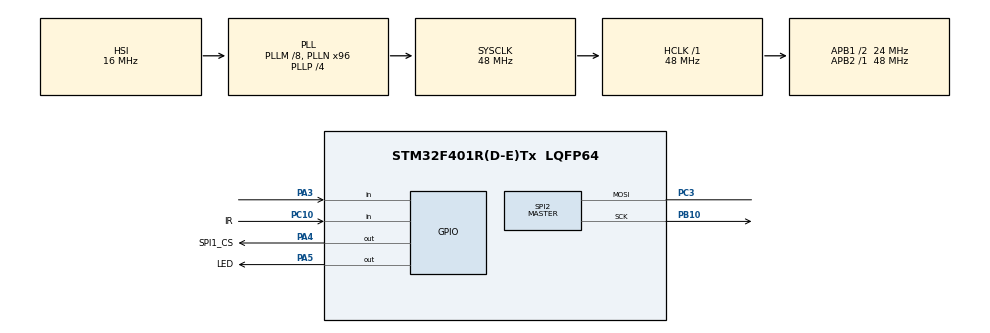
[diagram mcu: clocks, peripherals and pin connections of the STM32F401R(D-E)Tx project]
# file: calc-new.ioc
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Mcu.Family=STM32F4
PC3.Mode=Simplex_Bidirectional_Master
RCC.CortexFreq_Value=48000000
FREERTOS.Tasks01=calcTask,0,128,StartDefaultTask,Default,NULL,Dynamic,NULL,NULL
PC10.GPIO_Label=IR
SPI2.VirtualType=VM_MASTER
PB10.Mode=Simplex_Bidirectional_Master
PC10.Signal=GPIO_Input
PH1\ -\ OSC_OUT.Mode=HSE-External-Oscillator
RCC.APB1CLKDivider=RCC_HCLK_DIV2
PA5.PinState=GPIO_PIN_SET
RCC.SYSCLKSource=RCC_SYSCLKSOURCE_PLLCLK
ProjectManager.StackSize=0x400
PA13.Signal=SYS_JTMS-SWDIO
PH0\ -\ OSC_IN.Mode=HSE-External-Oscillator
PH0\ -\ OSC_IN.Signal=RCC_OSC_IN
ProjectManager.TargetToolchain=STM32CubeIDE
RCC.HCLKFreq_Value=48000000
RCC.APB2TimFreq_Value=48000000
PC3.Signal=SPI2_MOSI
TIM4.Prescaler=48-1
RCC.LSE_VALUE=32768
RCC.AHBFreq_Value=48000000
PB10.Signal=SPI2_SCK
PA5.Signal=GPIO_Output
RCC.HSE_VALUE=25000000
PH1\ -\ OSC_OUT.Signal=RCC_OSC_OUT
board=custom
RCC.VCOOutputFreq_Value=192000000
RCC.APB2Freq_Value=48000000
PA14.Mode=Serial_Wire
TIM4.Period=6553
VP_FREERTOS_VS_CMSIS_V1.Mode=CMSIS_V1
PA13.Mode=Serial_Wire
Mcu.Name=STM32F401R(D-E)Tx
RCC.48MHZClocksFreq_Value=48000000
PA4.Signal=GPIO_Output
RCC.SYSCLKFreq_VALUE=48000000
Mcu.Package=LQFP64
SPI2.Mode=SPI_MODE_MASTER
PA5.GPIO_Label=LED
PA14.Signal=SYS_JTCK-SWCLK
ProjectManager.HeapSize=0x200
RCC.HSI_VALUE=16000000
VP_TIM4_VS_ClockSourceINT.Mode=Internal
RCC.PLLP=RCC_PLLP_DIV4
NVIC.PriorityGroup=NVIC_PRIORITYGROUP_4
RCC.PLLM=8
RCC.PLLN=96
RCC.APB1TimFreq_Value=48000000
SPI2.Direction=SPI_DIRECTION_1LINE
RCC.APB1Freq_Value=24000000
PA4.GPIO_Label=SPI1_CS
PA3.Signal=GPIO_Input

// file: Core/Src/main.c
/* USER CODE BEGIN Header */
/**
  ******************************************************************************
  * @file           : main.c
  * @brief          : Main program body
  ******************************************************************************
  * @attention
  *
  * <h2><center>&copy; Copyright (c) 2021 STMicroelectronics.
  * All rights reserved.</center></h2>
  *
  * This software component is licensed by ST under BSD 3-Clause license,
  * the "License"; You may not use this file except in compliance with the
  * License. You may obtain a copy of the License at:
  *                        opensource.org/licenses/BSD-3-Clause
  *
  ******************************************************************************
  */
/* USER CODE END Header */
#include "main.h"
#include "cmsis_os.h"

/* USER CODE BEGIN Includes */
#include "ir_remote.h"
#include "tic8213.h"
#include "nec.h"
#include "calc.h"
#include "stm32f4xx_hal_tim.h"

/* USER CODE END Includes */

SPI_HandleTypeDef hspi2;

TIM_HandleTypeDef htim4;

osThreadId calcTaskHandle;

void SystemClock_Config(void);
static void MX_GPIO_Init(void);
static void MX_SPI2_Init(void);
static void MX_TIM4_Init(void);
void StartDefaultTask(void const * argument);

int main(void)
{

  /* MCU Configuration--------------------------------------------------------*/

  /* Reset of all peripherals, Initializes the Flash interface and the Systick. */
  HAL_Init();

  /* Configure the system clock */
  SystemClock_Config();

  /* Initialize all configured peripherals */
  MX_GPIO_Init();
  MX_SPI2_Init();
  MX_TIM4_Init();

  /* Create the thread(s) */
  /* definition and creation of calcTask */
  osThreadDef(calcTask, StartDefaultTask, osPriorityNormal, 0, 128);
  calcTaskHandle = osThreadCreate(osThread(calcTask), NULL);

  /* Start scheduler */
  osKernelStart();

  /* We should never get here as control is now taken by the scheduler */
  /* Infinite loop */
  while (1)
  {

  }
}

void SystemClock_Config(void)
{
  RCC_OscInitTypeDef RCC_OscInitStruct = {0};
  RCC_ClkInitTypeDef RCC_ClkInitStruct = {0};

  /** Configure the main internal regulator output voltage
  */
  __HAL_RCC_PWR_CLK_ENABLE();
  __HAL_PWR_VOLTAGESCALING_CONFIG(PWR_REGULATOR_VOLTAGE_SCALE2);
  /** Initializes the RCC Oscillators according to the specified parameters
  * in the RCC_OscInitTypeDef structure.
  */
  RCC_OscInitStruct.OscillatorType = RCC_OSCILLATORTYPE_HSI;
  RCC_OscInitStruct.HSIState = RCC_HSI_ON;
  RCC_OscInitStruct.HSICalibrationValue = RCC_HSICALIBRATION_DEFAULT;
  RCC_OscInitStruct.PLL.PLLState = RCC_PLL_ON;
  RCC_OscInitStruct.PLL.PLLSource = RCC_PLLSOURCE_HSI;
  RCC_OscInitStruct.PLL.PLLM = 8;
  RCC_OscInitStruct.PLL.PLLN = 96;
  RCC_OscInitStruct.PLL.PLLP = RCC_PLLP_DIV4;
  RCC_OscInitStruct.PLL.PLLQ = 4;
  if (HAL_RCC_OscConfig(&RCC_OscInitStruct) != HAL_OK)
  {
    Error_Handler();
  }
  /** Initializes the CPU, AHB and APB buses clocks
  */
  RCC_ClkInitStruct.ClockType = RCC_CLOCKTYPE_HCLK|RCC_CLOCKTYPE_SYSCLK
                              |RCC_CLOCKTYPE_PCLK1|RCC_CLOCKTYPE_PCLK2;
  RCC_ClkInitStruct.SYSCLKSource = RCC_SYSCLKSOURCE_PLLCLK;
  RCC_ClkInitStruct.AHBCLKDivider = RCC_SYSCLK_DIV1;
  RCC_ClkInitStruct.APB1CLKDivider = RCC_HCLK_DIV2;
  RCC_ClkInitStruct.APB2CLKDivider = RCC_HCLK_DIV1;

  if (HAL_RCC_ClockConfig(&RCC_ClkInitStruct, FLASH_LATENCY_1) != HAL_OK)
  {
    Error_Handler();
  }
}

static void MX_SPI2_Init(void)
{

  /* SPI2 parameter configuration*/
  hspi2.Instance = SPI2;
  hspi2.Init.Mode = SPI_MODE_MASTER;
  hspi2.Init.Direction = SPI_DIRECTION_1LINE;
  hspi2.Init.DataSize = SPI_DATASIZE_8BIT;
  hspi2.Init.CLKPolarity = SPI_POLARITY_LOW;
  hspi2.Init.CLKPhase = SPI_PHASE_1EDGE;
  hspi2.Init.NSS = SPI_NSS_SOFT;
  hspi2.Init.BaudRatePrescaler = SPI_BAUDRATEPRESCALER_2;
  hspi2.Init.FirstBit = SPI_FIRSTBIT_MSB;
  hspi2.Init.TIMode = SPI_TIMODE_DISABLE;
  hspi2.Init.CRCCalculation = SPI_CRCCALCULATION_DISABLE;
  hspi2.Init.CRCPolynomial = 10;
  if (HAL_SPI_Init(&hspi2) != HAL_OK)
  {
    Error_Handler();
  }

}

static void MX_TIM4_Init(void)
{

  TIM_ClockConfigTypeDef sClockSourceConfig = {0};
  TIM_MasterConfigTypeDef sMasterConfig = {0};

  htim4.Instance = TIM4;
  htim4.Init.Prescaler = 48-1;
  htim4.Init.CounterMode = TIM_COUNTERMODE_UP;
  htim4.Init.Period = 6553;
  htim4.Init.ClockDivision = TIM_CLOCKDIVISION_DIV1;
  htim4.Init.AutoReloadPreload = TIM_AUTORELOAD_PRELOAD_DISABLE;
  if (HAL_TIM_Base_Init(&htim4) != HAL_OK)
  {
    Error_Handler();
  }
  sClockSourceConfig.ClockSource = TIM_CLOCKSOURCE_INTERNAL;
  if (HAL_TIM_ConfigClockSource(&htim4, &sClockSourceConfig) != HAL_OK)
  {
    Error_Handler();
  }
  sMasterConfig.MasterOutputTrigger = TIM_TRGO_RESET;
  sMasterConfig.MasterSlaveMode = TIM_MASTERSLAVEMODE_DISABLE;
  if (HAL_TIMEx_MasterConfigSynchronization(&htim4, &sMasterConfig) != HAL_OK)
  {
    Error_Handler();
  }
  /* USER CODE BEGIN TIM4_Init 2 */
  HAL_TIM_Base_Start(&htim4);

  /* USER CODE END TIM4_Init 2 */

}

static void MX_GPIO_Init(void)
{
  GPIO_InitTypeDef GPIO_InitStruct = {0};

  /* GPIO Ports Clock Enable */
  __HAL_RCC_GPIOH_CLK_ENABLE();
  __HAL_RCC_GPIOC_CLK_ENABLE();
  __HAL_RCC_GPIOA_CLK_ENABLE();
  __HAL_RCC_GPIOB_CLK_ENABLE();

  /*Configure GPIO pin Output Level */
  HAL_GPIO_WritePin(SPI1_CS_GPIO_Port, SPI1_CS_Pin, GPIO_PIN_RESET);

  /*Configure GPIO pin Output Level */
  HAL_GPIO_WritePin(LED_GPIO_Port, LED_Pin, GPIO_PIN_SET);

  /*Configure GPIO pin : PA3 */
  GPIO_InitStruct.Pin = GPIO_PIN_3;
  GPIO_InitStruct.Mode = GPIO_MODE_INPUT;
  GPIO_InitStruct.Pull = GPIO_NOPULL;
  HAL_GPIO_Init(GPIOA, &GPIO_InitStruct);

  /*Configure GPIO pins : SPI1_CS_Pin LED_Pin */
  GPIO_InitStruct.Pin = SPI1_CS_Pin|LED_Pin;
  GPIO_InitStruct.Mode = GPIO_MODE_OUTPUT_PP;
  GPIO_InitStruct.Pull = GPIO_NOPULL;
  GPIO_InitStruct.Speed = GPIO_SPEED_FREQ_LOW;
  HAL_GPIO_Init(GPIOA, &GPIO_InitStruct);

  /*Configure GPIO pin : IR_Pin */
  GPIO_InitStruct.Pin = IR_Pin;
  GPIO_InitStruct.Mode = GPIO_MODE_INPUT;
  GPIO_InitStruct.Pull = GPIO_NOPULL;
  HAL_GPIO_Init(IR_GPIO_Port, &GPIO_InitStruct);

}

void StartDefaultTask(void const * argument)
{
  /* USER CODE BEGIN 5 */
  /* Infinite loop */
	clearDisplay();
  for(;;)
  {
	  calcTask();
	  osDelay(1);
  }
  /* USER CODE END 5 */
}

void Error_Handler(void)
{
  __disable_irq();
  while (1)
  {
  }
}

/************************ (C) COPYRIGHT STMicroelectronics *****END OF FILE****/
